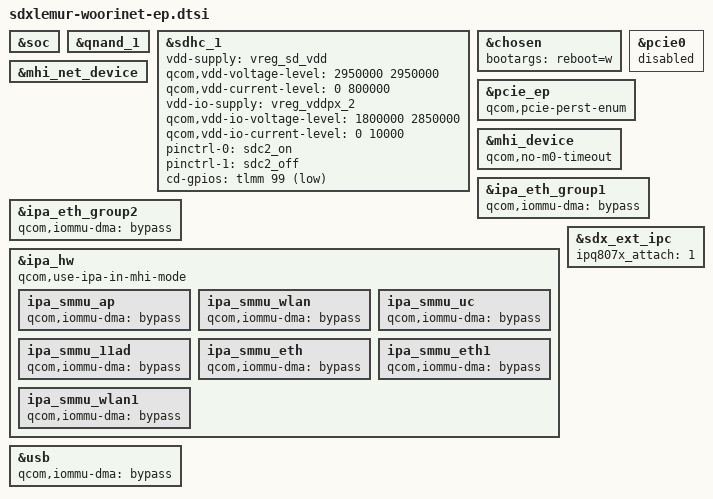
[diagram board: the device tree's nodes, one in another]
#include "sdxlemur-pmic-overlay.dtsi"

&soc {

};

&qnand_1 {
	status = "ok";
};

&sdhc_1 {
	status = "ok";

	vdd-supply = <&vreg_sd_vdd>;
	qcom,vdd-voltage-level = <2950000 2950000>;
	qcom,vdd-current-level = <0 800000>;

	vdd-io-supply = <&vreg_vddpx_2>;
	qcom,vdd-io-voltage-level = <1800000 2850000>;
	qcom,vdd-io-current-level = <0 10000>;

	pinctrl-names = "default", "sleep";
	pinctrl-0 = <&sdc2_on>;
	pinctrl-1 = <&sdc2_off>;

	cd-gpios = <&tlmm 99 GPIO_ACTIVE_LOW>;
};

&chosen {
	bootargs = "reboot=w";
};

&pcie0 {
	status = "disabled";
};

&pcie_ep {
	status = "ok";
	qcom,pcie-perst-enum;
};

&mhi_device {
	status = "ok";
	qcom,no-m0-timeout;
};

&mhi_net_device {
	status = "ok";
};

&ipa_eth_group1 {
	qcom,iommu-dma = "bypass";
};

&ipa_eth_group2 {
	qcom,iommu-dma = "bypass";
};

&ipa_hw {
	qcom,use-ipa-in-mhi-mode;
	ipa_smmu_ap {
		qcom,iommu-dma = "bypass";
	};

	ipa_smmu_wlan {
		qcom,iommu-dma = "bypass";
	};

	ipa_smmu_uc {
		qcom,iommu-dma = "bypass";
	};

	ipa_smmu_11ad {
		qcom,iommu-dma = "bypass";
	};

	ipa_smmu_eth {
		qcom,iommu-dma = "bypass";
	};

	ipa_smmu_eth1 {
		qcom,iommu-dma = "bypass";
	};

	ipa_smmu_wlan1 {
		qcom,iommu-dma = "bypass";
	};

};

&usb {
	qcom,iommu-dma = "bypass";
};

&sdx_ext_ipc {
	ipq807x_attach = <1>;
	status = "ok";
};
